# V32F20x_CM0 register map
File version: 1.0.1
CPU: CM0 r0p0, little endian, no MPU, no FPU, 2 interrupt priority bits
Registers are 32-bit, read-write, reset 0x0 unless marked. A register's access mark holds for its fields unless they carry their own. Offsets are from the block's base; [hi:lo] are bit positions; {n}, {i} and the like mark numbered series.

## UART14 — UART14 Peripheral Interface
Base 0x41030000
Same registers: UART15 0x41030800, UART16 0x41031000, UART17 0x41031800, UART18 0x41032000, UART19 0x41032800
0x00 RBR ro — Receive buffer register.
  [7:0] RBR — This register contains the data byte received on the serial input port sin in UART mode If in non FIFO mode the data in the RBR must be read before the next data arrives otherwise it will be overwritten resulting in an over run error
0x00 DLL (alternate view of RBR) — Divisor latch low register.
  [7:0] DLL — Divisor latch (low).
0x00 THR wo (alternate view of RBR) — Transmit holding register.
  [7:0] THR
0x04 DLH — Divisor latch high register.
  [7:0] DLH — Upper 8 bits of a 16 bit read write Divisor Latch register that contains the baud rate divisor for the UART
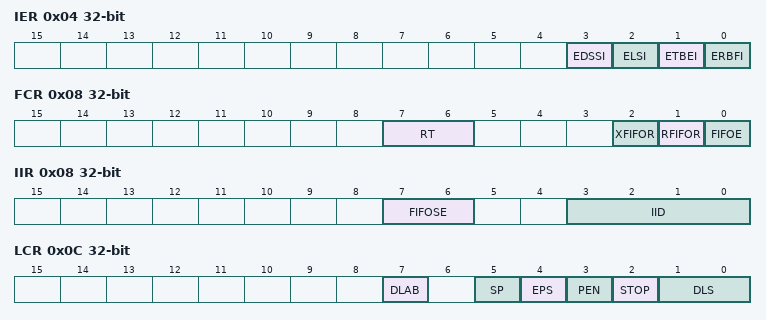
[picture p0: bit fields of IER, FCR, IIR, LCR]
0x04 IER (alternate view of DLH) — Interrupt enable register.
  [3] EDSSI — This is used to enable disable the generation of Modem Status Interrupt
  [2] ELSI — This is used to enable disable the generation of Receiver Line Status Interrupt
  [1] ETBEI — Enable Transmit Holding Register Empty Interrupt
  [0] ERBFI — Enable Received Data Available Interrupt
0x08 FCR wo — FIFO control register.
  [7:6] RT — This is used to select the trigger level in the receiver FIFO at which the Received Data Available Interrupt will be generated
  [2] XFIFOR — This resets the control portion of the transmit FIFO and treats the FIFO as empty
  [1] RFIFOR — This resets the control portion of the receive FIFO and treats the FIFO as empty
  [0] FIFOE — This bit enables disables the transmit and receive FIFOs
0x08 IIR (alternate view of FCR) — Interrupt identification register.
  [7:6] FIFOSE — This is used to indicate whether the FIFOs are enabled or disabled
  [3:0] IID — This indicates the highest priority pending interrupt which can be one of the following types specified in Values
0x0C LCR — Line control register.
  [7] DLAB — Divisor Latch Access Bit.
  [5] SP — Stick Parity.
  [4] EPS — Even Parity Select.
  [3] PEN — Parity Enable.
  [2] STOP — Number of stop bits.
  [1:0] DLS — Data Length Select.
0x10 MCR wo — Modem control register.
  [6] SIRE — This is used to enable/ disable the IrDA SIR Mode
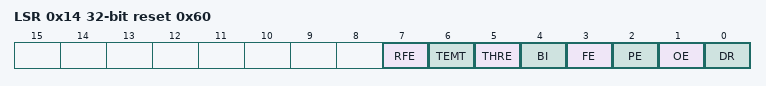
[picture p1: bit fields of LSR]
0x14 LSR ro reset 0x60 — Line status register.
  [7] RFE — Receiver FIFO Error bit.
  [6] TEMT — Transmitter Empty bit.
  [5] THRE — Transmit Holding Register Empty bit.
  [4] BI — Break Interrupt bit.
  [3] FE — Framing Error bit.
  [2] PE — Parity Error bit.
  [1] OE — Overrun error bit.
  [0] DR — Data Ready bit.
0x7C USR ro — UART status register.
  [0] BUSY — UART Busy.
0xC0 DLF — Divisor latch fraction register.
  [5:0] DLF — Fractional part of divisor.

## BTMR4 — BTMR4 Peripheral Interface
Base 0x41050000
Same registers: BTMR5 0x41050020, BTMR6 0x41050040, BTMR7 0x41050060, LPBTMR0 0x41108000, LPBTMR1 0x41109000
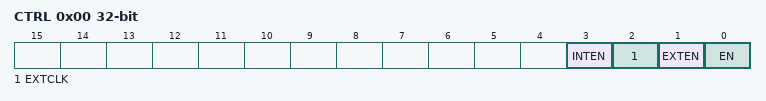
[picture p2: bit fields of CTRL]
0x00 CTRL — Timer0 control register.
  [3] INTEN — Timerx interrupt enable register.
  [2] EXTCLK — Select the external clock signal as the clock source
  [1] EXTEN — Select Timer external clock pin as the clock enable IO port
  [0] EN — Timerx enable control register.
0x04 VALUE — Timer0 real time counting register.
  [31:0] VALUE — Timerx real time counter register.
0x08 RELOAD — Timer0 reloads register.
  [31:0] RELOAD — Timerx reloads register
0x0C INTSTS — Timer0 interrupt status register.
  [0] INTSTS — Timerx interrupt status register.

## BPWM4 — BPWM4 Peripheral Interface
Base 0x41050100
Same registers: BPWM5 0x41050120, BPWM6 0x41050140, BPWM7 0x41050160
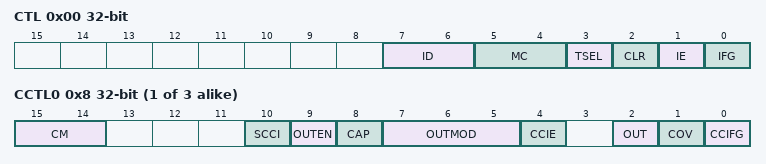
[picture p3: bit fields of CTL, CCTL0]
0x00 CTL — BPWM Timer control register.
  [7:6] ID — PWM Timerx input clock divide control.
  [5:4] MC — PWM Timer control.
  [3] TSEL — Clock source selected
  [2] CLR — TAR clear register
  [1] IE — PWM Timerx interrupt enable register.
  [0] IFG — PWM Timerx interrupt status flag bit
0x04 TAR ro — BPWM Timer real time counting register.
  [31:0] TAR — PWM Timerx real time counting register.
{0x8+4i} CCTL{i} (i=0..2) — BPWM Timer compare/capture control register.
  [15:14] CM — Capture edge selection.
  [10] SCCI — When TAR is equal to CCRx the electricity level status of current channel input pins
  [9] OUTEN — OUTx output enable control register.
  [8] CAP — Capture/compare mode selection.
  [7:5] OUTMOD — Output mode selection.
  [4] CCIE — Capture /compare interrupt enable register.
  [2] OUT — When OUTMOD set 0 the bit is used to control the output value of OUTx
  [1] COV — Capture overflows flag bit
  [0] CCIFG — Under the capture mode when capture event happened the bit will set 1 and TAR will be locked in CCRx
{0x14+4i} CCR{i} (i=0..2) — BPWM Timer compare/ capture data register .
  [15:0] CCRx — Compare / capture data register
